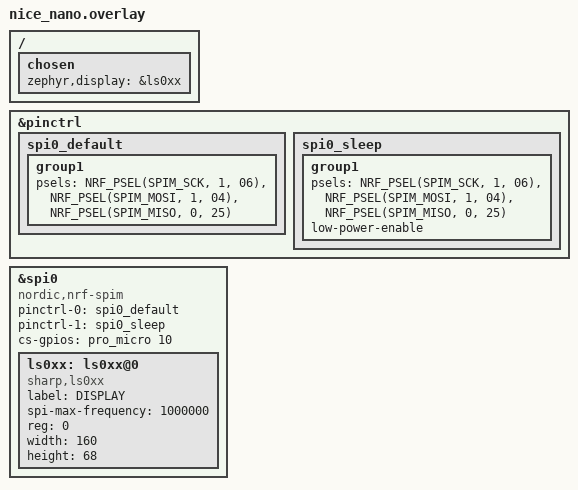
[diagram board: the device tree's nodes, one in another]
/*
 * Copyright (c) 2024 Curtis Bollinger
 *
 * SPDX-License-Identifier: MIT
 */

&pinctrl {
    spi0_default: spi0_default {
        group1 {
            psels = <NRF_PSEL(SPIM_SCK, 1, 06)>,  // P9 (D9)
                    <NRF_PSEL(SPIM_MOSI, 1, 04)>, // P8 (D8)
                    <NRF_PSEL(SPIM_MISO, 0, 25)>;
        };
    };
    spi0_sleep: spi0_sleep {
        group1 {
            psels = <NRF_PSEL(SPIM_SCK, 1, 06)>,
                    <NRF_PSEL(SPIM_MOSI, 1, 04)>,
                    <NRF_PSEL(SPIM_MISO, 0, 25)>;
            low-power-enable;
        };
    };
};

nice_view_spi: &spi0 {
    compatible = "nordic,nrf-spim";
    pinctrl-0 = <&spi0_default>;
    pinctrl-1 = <&spi0_sleep>;
    pinctrl-names = "default", "sleep";
    cs-gpios = <&pro_micro 10 GPIO_ACTIVE_HIGH>; // P10 (CS)
    status = "okay";

    ls0xx: ls0xx@0 {
        compatible = "sharp,ls0xx";
        label = "DISPLAY";
        spi-max-frequency = <1000000>;
        reg = <0>;
        width = <160>;
        height = <68>;
    };
};

/ {
    chosen {
        zephyr,display = &ls0xx;
    };
};
